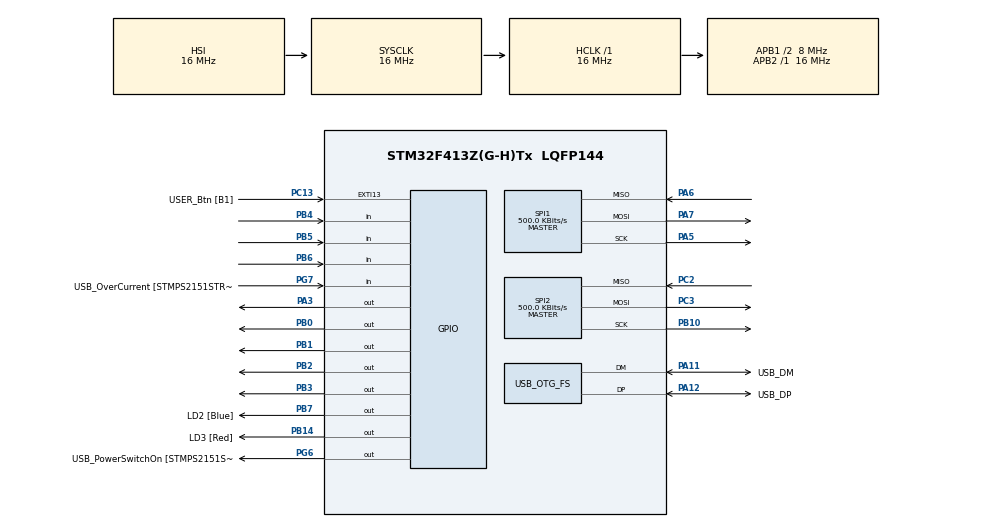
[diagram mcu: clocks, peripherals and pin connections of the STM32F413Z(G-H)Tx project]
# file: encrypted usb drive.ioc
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Mcu.Family=STM32F4
Mcu.Name=STM32F413Z(G-H)Tx
Mcu.Package=LQFP144
NVIC.OTG_FS_IRQn=true\:0\:0\:false\:false\:true\:false\:true\:true
NVIC.PriorityGroup=NVIC_PRIORITYGROUP_4
NVIC.TIM7_IRQn=true\:0\:0\:false\:false\:true\:true\:true\:true
PA10.GPIO_Label=USB_ID
PA10.Signal=USB_OTG_FS_ID
PA11.GPIO_Label=USB_DM
PA11.Mode=Device_Only
PA11.Signal=USB_OTG_FS_DM
PA12.GPIO_Label=USB_DP
PA12.Mode=Device_Only
PA12.Signal=USB_OTG_FS_DP
PA13.GPIO_Label=TMS
PA13.Signal=SYS_JTMS-SWDIO
PA14.GPIO_Label=TCK
PA14.Signal=SYS_JTCK-SWCLK
PA3.Signal=GPIO_Output
PA5.Mode=Full_Duplex_Master
PA5.Signal=SPI1_SCK
PA6.Mode=Full_Duplex_Master
PA6.Signal=SPI1_MISO
PA7.Mode=Full_Duplex_Master
PA7.Signal=SPI1_MOSI
PA8.GPIO_Label=USB_SOF [TP1]
PA8.Signal=USB_OTG_FS_SOF
PA9.GPIO_Label=USB_VBUS
PA9.Signal=USB_OTG_FS_VBUS
PB0.Signal=GPIO_Output
PB1.Signal=GPIO_Output
PB10.Mode=Full_Duplex_Master
PB10.Signal=SPI2_SCK
PB12.Signal=SPI2_NSS
PB14.GPIO_Label=LD3 [Red]
PB14.Signal=GPIO_Output
PB2.Signal=GPIO_Output
PB3.Signal=GPIO_Output
PB4.GPIO_PuPd=GPIO_PULLDOWN
PB4.Signal=GPIO_Input
PB5.GPIO_PuPd=GPIO_PULLDOWN
PB5.Signal=GPIO_Input
PB6.GPIO_PuPd=GPIO_PULLDOWN
PB6.Signal=GPIO_Input
PB7.GPIO_Label=LD2 [Blue]
PB7.Signal=GPIO_Output
PC13.GPIO_Label=USER_Btn [B1]
PC13.Signal=GPXTI13
PC14-OSC32_IN.Mode=LSE-External-Oscillator
PC14-OSC32_IN.Signal=RCC_OSC32_IN
PC15-OSC32_OUT.Mode=LSE-External-Oscillator
PC15-OSC32_OUT.Signal=RCC_OSC32_OUT
PC2.Mode=Full_Duplex_Master
PC2.Signal=SPI2_MISO
PC3.Mode=Full_Duplex_Master
PC3.Signal=SPI2_MOSI
PD8.GPIO_Label=STLK_RX [STM32F103CBT6_PA3]
PD8.Signal=USART3_TX
PD9.GPIO_Label=STLK_TX [STM32F103CBT6_PA2]
PD9.Signal=USART3_RX
PG6.GPIO_Label=USB_PowerSwitchOn [STMPS2151STR_EN]
PG6.Signal=GPIO_Output
PG7.GPIO_Label=USB_OverCurrent [STMPS2151STR_FAULT]
PG7.Signal=GPIO_Input
PH0\ -\ OSC_IN.GPIO_Label=MCO
PH0\ -\ OSC_IN.Mode=HSE-External-Clock-Source
PH0\ -\ OSC_IN.Signal=RCC_OSC_IN
PH1\ -\ OSC_OUT.Mode=HSE-External-Clock-Source
PH1\ -\ OSC_OUT.Signal=RCC_OSC_OUT
ProjectManager.HeapSize=0x200
ProjectManager.StackSize=0x400
ProjectManager.TargetToolchain=STM32CubeIDE
RCC.48MHZClocksFreq_Value=24000000
RCC.AHBFreq_Value=16000000
RCC.APB1CLKDivider=RCC_HCLK_DIV2
RCC.APB1Freq_Value=8000000
RCC.APB1TimFreq_Value=16000000
RCC.APB2Freq_Value=16000000
RCC.APB2TimFreq_Value=16000000
RCC.CortexFreq_Value=16000000
RCC.HCLKFreq_Value=16000000
RCC.HSE_VALUE=8000000
RCC.HSI_VALUE=16000000
RCC.PLLM=4
RCC.PLLMUL=RCC_PLL_MUL9
RCC.PLLN=72
RCC.PLLQ=3
RCC.PRESCALERUSB=RCC_USBCLKSOURCE_PLL_DIV1_5
RCC.SYSCLKFreq_VALUE=16000000
RCC.SYSCLKSourceVirtual=RCC_SYSCLKSOURCE_PLLCLK
RCC.USBFreq_Value=48000000
RCC.VCOOutputFreq_Value=144000000
SPI1.BaudRatePrescaler=SPI_BAUDRATEPRESCALER_32
SPI1.CLKPhase=SPI_PHASE_2EDGE
SPI1.CLKPolarity=SPI_POLARITY_HIGH
SPI1.CalculateBaudRate=500.0 KBits/s
SPI1.Direction=SPI_DIRECTION_2LINES
SPI1.FirstBit=SPI_FIRSTBIT_MSB
SPI1.Mode=SPI_MODE_MASTER
SPI1.VirtualType=VM_MASTER
SPI2.BaudRatePrescaler=SPI_BAUDRATEPRESCALER_16
SPI2.CLKPhase=SPI_PHASE_2EDGE
SPI2.CLKPolarity=SPI_POLARITY_HIGH
SPI2.CalculateBaudRate=500.0 KBits/s
SPI2.Direction=SPI_DIRECTION_2LINES
SPI2.Mode=SPI_MODE_MASTER
SPI2.VirtualType=VM_MASTER
TIM7.Period=4
TIM7.Prescaler=7999
TIM7.TIM_MasterOutputTrigger=TIM_TRGO_RESET
USB_DEVICE.CLASS_NAME_FS=CDC
USB_DEVICE.VirtualMode=Cdc
USB_DEVICE.VirtualModeFS=Cdc_FS
USB_OTG_FS.VirtualMode=Device_Only
VP_TIM7_VS_ClockSourceINT.Mode=Enable_Timer
VP_USB_DEVICE_VS_USB_DEVICE_CDC_FS.Mode=CDC_FS
board=NUCLEO-F413ZH

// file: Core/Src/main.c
/* USER CODE BEGIN Header */
/**
  ******************************************************************************
  * @file           : main.c
  * @brief          : Main program body
  ******************************************************************************
  * @attention
  *
  * Copyright (c) 2025 STMicroelectronics.
  * All rights reserved.
  *
  * This software is licensed under terms that can be found in the LICENSE file
  * in the root directory of this software component.
  * If no LICENSE file comes with this software, it is provided AS-IS.
  *
  ******************************************************************************
  */
/* USER CODE END Header */
#include "main.h"
#include "usb_device.h"

/* USER CODE BEGIN Includes */
#include "keypad.h"
#include "lcd.h"
/* USER CODE END Includes */

SPI_HandleTypeDef hspi1;
SPI_HandleTypeDef hspi2;

TIM_HandleTypeDef htim7;

void SystemClock_Config(void);
static void MX_GPIO_Init(void);
static void MX_TIM7_Init(void);
static void MX_SPI1_Init(void);
static void MX_SPI2_Init(void);
static void MX_USB_DEVICE_Init(void);

int main(void)
{

  /* MCU Configuration--------------------------------------------------------*/

  /* Reset of all peripherals, Initializes the Flash interface and the Systick. */
  HAL_Init();

  /* Configure the system clock */
  SystemClock_Config();

  /* Initialize all configured peripherals */
  MX_GPIO_Init();
  MX_TIM7_Init();
  MX_SPI1_Init();
  MX_SPI2_Init();
  MX_USB_DEVICE_Init();
  /* USER CODE BEGIN 2 */
  HAL_TIM_Base_Start_IT(&htim7); // Start timer
  /* USER CODE END 2 */

  /* Infinite loop */
  /* USER CODE BEGIN WHILE */
//  lcd_init(&hspi1);
//  lcd_cursor_on(&hspi1);
  HAL_GPIO_WritePin(GPIOA, GPIO_PIN_3, GPIO_PIN_RESET);
  lcd_clear(&hspi2);
//  lcd_off(&hspi2);
  lcd_on(&hspi2);
  lcd_welcome(&hspi2);
  while (1)
  {
//	  lcd_clear(&hspi2);
//	  HAL_Delay(1000);
//	  lcd_cursor_on(&hspi1);
//	  lcd_init(&hspi1);
//	  lcd_cursor_on(&hspi1);
//	  HAL_Delay(1000);
//	  uint8_t tx_buffer[] = "w";
//	  lcd_display_first_row(&hspi1, tx_buffer);
//	  lcd_display_second_row(&hspi1, "ece 477");
//	  periodic_send(&hspi1);
    /* USER CODE END WHILE */

  }
}

void SystemClock_Config(void)
{
  RCC_OscInitTypeDef RCC_OscInitStruct = {0};
  RCC_ClkInitTypeDef RCC_ClkInitStruct = {0};

  /** Configure the main internal regulator output voltage
  */
  __HAL_RCC_PWR_CLK_ENABLE();
  __HAL_PWR_VOLTAGESCALING_CONFIG(PWR_REGULATOR_VOLTAGE_SCALE1);

  /** Initializes the RCC Oscillators according to the specified parameters
  * in the RCC_OscInitTypeDef structure.
  */
  RCC_OscInitStruct.OscillatorType = RCC_OSCILLATORTYPE_HSI|RCC_OSCILLATORTYPE_HSE;
  RCC_OscInitStruct.HSEState = RCC_HSE_BYPASS;
  RCC_OscInitStruct.HSIState = RCC_HSI_ON;
  RCC_OscInitStruct.HSICalibrationValue = RCC_HSICALIBRATION_DEFAULT;
  RCC_OscInitStruct.PLL.PLLState = RCC_PLL_ON;
  RCC_OscInitStruct.PLL.PLLSource = RCC_PLLSOURCE_HSE;
  RCC_OscInitStruct.PLL.PLLM = 4;
  RCC_OscInitStruct.PLL.PLLN = 72;
  RCC_OscInitStruct.PLL.PLLP = RCC_PLLP_DIV2;
  RCC_OscInitStruct.PLL.PLLQ = 3;
  RCC_OscInitStruct.PLL.PLLR = 2;
  if (HAL_RCC_OscConfig(&RCC_OscInitStruct) != HAL_OK)
  {
    Error_Handler();
  }

  /** Initializes the CPU, AHB and APB buses clocks
  */
  RCC_ClkInitStruct.ClockType = RCC_CLOCKTYPE_HCLK|RCC_CLOCKTYPE_SYSCLK
                              |RCC_CLOCKTYPE_PCLK1|RCC_CLOCKTYPE_PCLK2;
  RCC_ClkInitStruct.SYSCLKSource = RCC_SYSCLKSOURCE_HSI;
  RCC_ClkInitStruct.AHBCLKDivider = RCC_SYSCLK_DIV1;
  RCC_ClkInitStruct.APB1CLKDivider = RCC_HCLK_DIV2;
  RCC_ClkInitStruct.APB2CLKDivider = RCC_HCLK_DIV1;

  if (HAL_RCC_ClockConfig(&RCC_ClkInitStruct, FLASH_LATENCY_0) != HAL_OK)
  {
    Error_Handler();
  }
}

static void MX_SPI1_Init(void)
{

  /* SPI1 parameter configuration*/
  hspi1.Instance = SPI1;
  hspi1.Init.Mode = SPI_MODE_MASTER;
  hspi1.Init.Direction = SPI_DIRECTION_2LINES;
  hspi1.Init.DataSize = SPI_DATASIZE_8BIT;
  hspi1.Init.CLKPolarity = SPI_POLARITY_HIGH;
  hspi1.Init.CLKPhase = SPI_PHASE_2EDGE;
  hspi1.Init.NSS = SPI_NSS_SOFT;
  hspi1.Init.BaudRatePrescaler = SPI_BAUDRATEPRESCALER_32;
  hspi1.Init.FirstBit = SPI_FIRSTBIT_MSB;
  hspi1.Init.TIMode = SPI_TIMODE_DISABLE;
  hspi1.Init.CRCCalculation = SPI_CRCCALCULATION_DISABLE;
  hspi1.Init.CRCPolynomial = 10;
  if (HAL_SPI_Init(&hspi1) != HAL_OK)
  {
    Error_Handler();
  }

}

static void MX_SPI2_Init(void)
{

  /* SPI2 parameter configuration*/
  hspi2.Instance = SPI2;
  hspi2.Init.Mode = SPI_MODE_MASTER;
  hspi2.Init.Direction = SPI_DIRECTION_2LINES;
  hspi2.Init.DataSize = SPI_DATASIZE_8BIT;
  hspi2.Init.CLKPolarity = SPI_POLARITY_HIGH;
  hspi2.Init.CLKPhase = SPI_PHASE_2EDGE;
  hspi2.Init.NSS = SPI_NSS_SOFT;
  hspi2.Init.BaudRatePrescaler = SPI_BAUDRATEPRESCALER_16;
  hspi2.Init.FirstBit = SPI_FIRSTBIT_MSB;
  hspi2.Init.TIMode = SPI_TIMODE_DISABLE;
  hspi2.Init.CRCCalculation = SPI_CRCCALCULATION_DISABLE;
  hspi2.Init.CRCPolynomial = 10;
  if (HAL_SPI_Init(&hspi2) != HAL_OK)
  {
    Error_Handler();
  }

}

static void MX_TIM7_Init(void)
{

  TIM_MasterConfigTypeDef sMasterConfig = {0};

  htim7.Instance = TIM7;
  htim7.Init.Prescaler = 7999;
  htim7.Init.CounterMode = TIM_COUNTERMODE_UP;
  htim7.Init.Period = 4;
  htim7.Init.AutoReloadPreload = TIM_AUTORELOAD_PRELOAD_DISABLE;
  if (HAL_TIM_Base_Init(&htim7) != HAL_OK)
  {
    Error_Handler();
  }
  sMasterConfig.MasterOutputTrigger = TIM_TRGO_RESET;
  sMasterConfig.MasterSlaveMode = TIM_MASTERSLAVEMODE_DISABLE;
  if (HAL_TIMEx_MasterConfigSynchronization(&htim7, &sMasterConfig) != HAL_OK)
  {
    Error_Handler();
  }

}

static void MX_GPIO_Init(void)
{
  GPIO_InitTypeDef GPIO_InitStruct = {0};

  /* GPIO Ports Clock Enable */
  __HAL_RCC_GPIOC_CLK_ENABLE();
  __HAL_RCC_GPIOH_CLK_ENABLE();
  __HAL_RCC_GPIOA_CLK_ENABLE();
  __HAL_RCC_GPIOB_CLK_ENABLE();
  __HAL_RCC_GPIOD_CLK_ENABLE();
  __HAL_RCC_GPIOG_CLK_ENABLE();

  /*Configure GPIO pin Output Level */
  HAL_GPIO_WritePin(GPIOA, GPIO_PIN_3, GPIO_PIN_RESET);

  /*Configure GPIO pin Output Level */
  HAL_GPIO_WritePin(GPIOB, GPIO_PIN_0|GPIO_PIN_1|GPIO_PIN_2|LD3_Pin
                          |GPIO_PIN_3|LD2_Pin, GPIO_PIN_RESET);

  /*Configure GPIO pin Output Level */
  HAL_GPIO_WritePin(USB_PowerSwitchOn_GPIO_Port, USB_PowerSwitchOn_Pin, GPIO_PIN_RESET);

  /*Configure GPIO pin : USER_Btn_Pin */
  GPIO_InitStruct.Pin = USER_Btn_Pin;
  GPIO_InitStruct.Mode = GPIO_MODE_IT_RISING;
  GPIO_InitStruct.Pull = GPIO_NOPULL;
  HAL_GPIO_Init(USER_Btn_GPIO_Port, &GPIO_InitStruct);

  /*Configure GPIO pin : PA3 */
  GPIO_InitStruct.Pin = GPIO_PIN_3;
  GPIO_InitStruct.Mode = GPIO_MODE_OUTPUT_PP;
  GPIO_InitStruct.Pull = GPIO_NOPULL;
  GPIO_InitStruct.Speed = GPIO_SPEED_FREQ_LOW;
  HAL_GPIO_Init(GPIOA, &GPIO_InitStruct);

  /*Configure GPIO pins : PB0 PB1 PB2 LD3_Pin
                           PB3 LD2_Pin */
  GPIO_InitStruct.Pin = GPIO_PIN_0|GPIO_PIN_1|GPIO_PIN_2|LD3_Pin
                          |GPIO_PIN_3|LD2_Pin;
  GPIO_InitStruct.Mode = GPIO_MODE_OUTPUT_PP;
  GPIO_InitStruct.Pull = GPIO_NOPULL;
  GPIO_InitStruct.Speed = GPIO_SPEED_FREQ_LOW;
  HAL_GPIO_Init(GPIOB, &GPIO_InitStruct);

  /*Configure GPIO pins : STLK_RX_Pin STLK_TX_Pin */
  GPIO_InitStruct.Pin = STLK_RX_Pin|STLK_TX_Pin;
  GPIO_InitStruct.Mode = GPIO_MODE_AF_PP;
  GPIO_InitStruct.Pull = GPIO_NOPULL;
  GPIO_InitStruct.Speed = GPIO_SPEED_FREQ_VERY_HIGH;
  GPIO_InitStruct.Alternate = GPIO_AF7_USART3;
  HAL_GPIO_Init(GPIOD, &GPIO_InitStruct);

  /*Configure GPIO pin : USB_PowerSwitchOn_Pin */
  GPIO_InitStruct.Pin = USB_PowerSwitchOn_Pin;
  GPIO_InitStruct.Mode = GPIO_MODE_OUTPUT_PP;
  GPIO_InitStruct.Pull = GPIO_NOPULL;
  GPIO_InitStruct.Speed = GPIO_SPEED_FREQ_LOW;
  HAL_GPIO_Init(USB_PowerSwitchOn_GPIO_Port, &GPIO_InitStruct);

  /*Configure GPIO pin : USB_OverCurrent_Pin */
  GPIO_InitStruct.Pin = USB_OverCurrent_Pin;
  GPIO_InitStruct.Mode = GPIO_MODE_INPUT;
  GPIO_InitStruct.Pull = GPIO_NOPULL;
  HAL_GPIO_Init(USB_OverCurrent_GPIO_Port, &GPIO_InitStruct);

  /*Configure GPIO pins : PB4 PB5 PB6 */
  GPIO_InitStruct.Pin = GPIO_PIN_4|GPIO_PIN_5|GPIO_PIN_6;
  GPIO_InitStruct.Mode = GPIO_MODE_INPUT;
  GPIO_InitStruct.Pull = GPIO_PULLDOWN;
  HAL_GPIO_Init(GPIOB, &GPIO_InitStruct);

}

void Error_Handler(void)
{
  __disable_irq();
  while (1)
  {
  }
}
